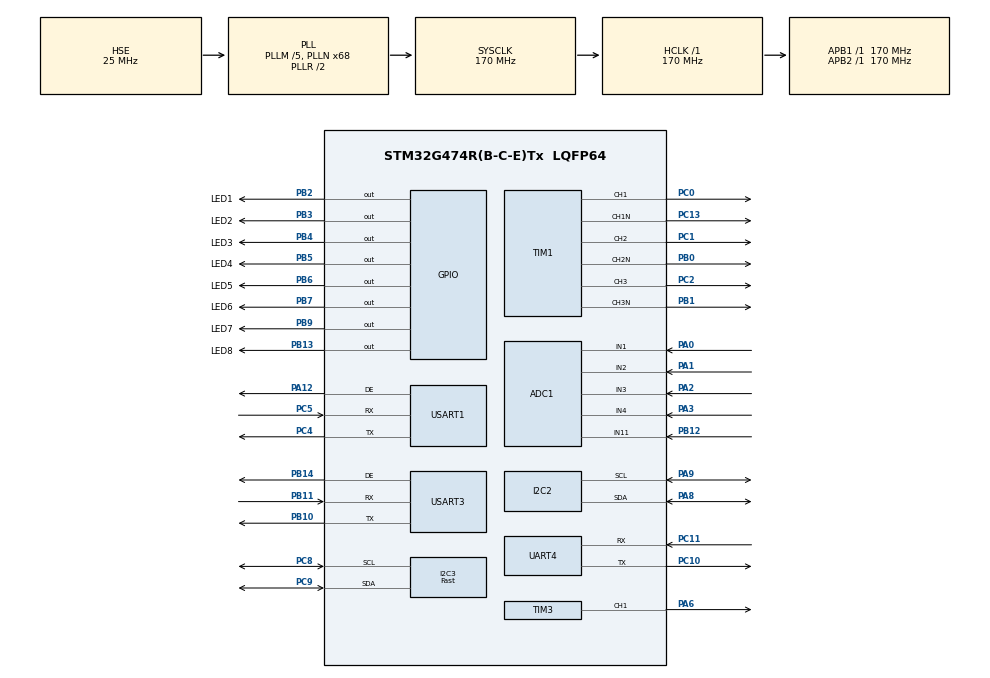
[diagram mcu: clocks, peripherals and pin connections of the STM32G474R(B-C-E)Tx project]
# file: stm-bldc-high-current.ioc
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ADC1.Channel-0\#ChannelRegularConversion=ADC_CHANNEL_1
ADC1.Channel-1\#ChannelRegularConversion=ADC_CHANNEL_2
ADC1.Channel-2\#ChannelRegularConversion=ADC_CHANNEL_3
ADC1.Channel-3\#ChannelRegularConversion=ADC_CHANNEL_4
ADC1.ContinuousConvMode=DISABLE
ADC1.DMAContinuousRequests=ENABLE
ADC1.EOCSelection=ADC_EOC_SEQ_CONV
ADC1.ExternalTrigConv=ADC_EXTERNALTRIG_T1_TRGO2
ADC1.ExternalTrigConvEdge=ADC_EXTERNALTRIGCONVEDGE_RISING
ADC1.NbrOfConversion=4
ADC1.NbrOfConversionFlag=1
ADC1.OffsetNumber-0\#ChannelRegularConversion=ADC_OFFSET_NONE
ADC1.OffsetNumber-1\#ChannelRegularConversion=ADC_OFFSET_NONE
ADC1.OffsetNumber-2\#ChannelRegularConversion=ADC_OFFSET_NONE
ADC1.OffsetNumber-3\#ChannelRegularConversion=ADC_OFFSET_NONE
ADC1.Overrun=ADC_OVR_DATA_OVERWRITTEN
ADC1.Rank-0\#ChannelRegularConversion=1
ADC1.Rank-1\#ChannelRegularConversion=2
ADC1.Rank-2\#ChannelRegularConversion=3
ADC1.Rank-3\#ChannelRegularConversion=4
ADC1.SamplingTime-0\#ChannelRegularConversion=ADC_SAMPLETIME_2CYCLES_5
ADC1.SamplingTime-1\#ChannelRegularConversion=ADC_SAMPLETIME_2CYCLES_5
ADC1.SamplingTime-2\#ChannelRegularConversion=ADC_SAMPLETIME_2CYCLES_5
ADC1.SamplingTime-3\#ChannelRegularConversion=ADC_SAMPLETIME_12CYCLES_5
ADC1.master=1
Dma.ADC1.0.Direction=DMA_PERIPH_TO_MEMORY
Dma.ADC1.0.EventEnable=DISABLE
Dma.ADC1.0.Instance=DMA1_Channel1
Dma.ADC1.0.MemDataAlignment=DMA_MDATAALIGN_HALFWORD
Dma.ADC1.0.MemInc=DMA_MINC_ENABLE
Dma.ADC1.0.Mode=DMA_CIRCULAR
Dma.ADC1.0.PeriphDataAlignment=DMA_PDATAALIGN_HALFWORD
Dma.ADC1.0.PeriphInc=DMA_PINC_DISABLE
Dma.ADC1.0.Polarity=HAL_DMAMUX_REQ_GEN_RISING
Dma.ADC1.0.Priority=DMA_PRIORITY_LOW
Dma.ADC1.0.RequestNumber=1
Dma.ADC1.0.SignalID=NONE
Dma.ADC1.0.SyncEnable=DISABLE
Dma.ADC1.0.SyncPolarity=HAL_DMAMUX_SYNC_NO_EVENT
Dma.ADC1.0.SyncRequestNumber=1
Dma.ADC1.0.SyncSignalID=NONE
Dma.Request0=ADC1
I2C2.Timing=0x40B285C2
I2C3.I2C_Speed_Mode=I2C_Fast
I2C3.Timing=0x40621236
Mcu.Family=STM32G4
Mcu.Name=STM32G474R(B-C-E)Tx
Mcu.Package=LQFP64
NVIC.I2C3_EV_IRQn=true\:0\:0\:false\:false\:true\:true\:true\:true
NVIC.PriorityGroup=NVIC_PRIORITYGROUP_4
NVIC.TIM1_UP_TIM16_IRQn=true\:0\:0\:false\:false\:true\:true\:true\:true
PA0.Mode=IN1-Single-Ended
PA0.Signal=ADC1_IN1
PA1.Mode=IN2-Single-Ended
PA1.Signal=ADC1_IN2
PA12.Mode=Hardware Flow Control (RS485)
PA12.Signal=USART1_DE
PA13.Mode=Serial_Wire
PA13.Signal=SYS_JTMS-SWDIO
PA14.Mode=Serial_Wire
PA14.Signal=SYS_JTCK-SWCLK
PA2.Mode=IN3-Single-Ended
PA2.Signal=ADC1_IN3
PA3.Mode=IN4-Single-Ended
PA3.Signal=ADC1_IN4
PA6.Signal=S_TIM3_CH1
PA8.Mode=I2C
PA8.Signal=I2C2_SDA
PA9.Mode=I2C
PA9.Signal=I2C2_SCL
PB0.Mode=PWM Generation2 CH2 CH2N
PB0.Signal=TIM1_CH2N
PB1.Mode=PWM Generation3 CH3 CH3N
PB1.Signal=TIM1_CH3N
PB10.Mode=Asynchronous
PB10.Signal=USART3_TX
PB11.Mode=Asynchronous
PB11.Signal=USART3_RX
PB12.Mode=IN11-Single-Ended
PB12.Signal=ADC1_IN11
PB13.GPIO_Label=LED8
PB13.Signal=GPIO_Output
PB14.Mode=Hardware Flow Control (RS485)
PB14.Signal=USART3_DE
PB2.GPIO_Label=LED1
PB2.Signal=GPIO_Output
PB3.GPIO_Label=LED2
PB3.Signal=GPIO_Output
PB4.GPIO_Label=LED3
PB4.Signal=GPIO_Output
PB5.GPIO_Label=LED4
PB5.Signal=GPIO_Output
PB6.GPIO_Label=LED5
PB6.Signal=GPIO_Output
PB7.GPIO_Label=LED6
PB7.Signal=GPIO_Output
PB9.GPIO_Label=LED7
PB9.Signal=GPIO_Output
PC0.Signal=S_TIM1_CH1
PC1.Signal=S_TIM1_CH2
PC10.Mode=Asynchronous
PC10.Signal=UART4_TX
PC11.Mode=Asynchronous
PC11.Signal=UART4_RX
PC13.Mode=PWM Generation1 CH1 CH1N
PC13.Signal=TIM1_CH1N
PC2.Signal=S_TIM1_CH3
PC4.Mode=Asynchronous
PC4.Signal=USART1_TX
PC5.Mode=Asynchronous
PC5.Signal=USART1_RX
PC8.Mode=I2C
PC8.Signal=I2C3_SCL
PC9.Mode=I2C
PC9.Signal=I2C3_SDA
PF0-OSC_IN.Mode=HSE-External-Oscillator
PF0-OSC_IN.Signal=RCC_OSC_IN
PF1-OSC_OUT.Mode=HSE-External-Oscillator
PF1-OSC_OUT.Signal=RCC_OSC_OUT
ProjectManager.HeapSize=0x200
ProjectManager.StackSize=0x400
ProjectManager.TargetToolchain=STM32CubeIDE
RCC.ADC12Freq_Value=170000000
RCC.ADC345Freq_Value=170000000
RCC.AHBFreq_Value=170000000
RCC.APB1Freq_Value=170000000
RCC.APB1TimFreq_Value=170000000
RCC.APB2Freq_Value=170000000
RCC.APB2TimFreq_Value=170000000
RCC.CortexFreq_Value=170000000
RCC.EXTERNAL_CLOCK_VALUE=12288000
RCC.HCLKFreq_Value=170000000
RCC.HSE_VALUE=25000000
RCC.HSI48_VALUE=48000000
RCC.HSI_VALUE=16000000
RCC.LSE_VALUE=32768
RCC.PLLM=RCC_PLLM_DIV5
RCC.PLLN=68
RCC.PLLSourceVirtual=RCC_PLLSOURCE_HSE
RCC.SYSCLKFreq_VALUE=170000000
RCC.SYSCLKSource=RCC_SYSCLKSOURCE_PLLCLK
RCC.USBFreq_Value=170000000
RCC.VCOOutputFreq_Value=340000000
SH.S_TIM1_CH1.0=TIM1_CH1,PWM Generation1 CH1 CH1N
SH.S_TIM1_CH2.0=TIM1_CH2,PWM Generation2 CH2 CH2N
SH.S_TIM1_CH3.0=TIM1_CH3,PWM Generation3 CH3 CH3N
SH.S_TIM3_CH1.0=TIM3_CH1,PWM Generation1 CH1
TIM1.AutoReloadPreload=TIM_AUTORELOAD_PRELOAD_ENABLE
TIM1.Channel-PWM\ Generation1\ CH1\ CH1N=TIM_CHANNEL_1
TIM1.Channel-PWM\ Generation2\ CH2\ CH2N=TIM_CHANNEL_2
TIM1.Channel-PWM\ Generation3\ CH3\ CH3N=TIM_CHANNEL_3
TIM1.Channel-PWM\ Generation6\ No\ Output=TIM_CHANNEL_6
TIM1.CounterMode=TIM_COUNTERMODE_CENTERALIGNED1
TIM1.DeadTime=65
TIM1.OCMode_PWM-PWM\ Generation1\ CH1\ CH1N=TIM_OCMODE_PWM1
TIM1.PulseNoDither_6=5
TIM1.TIM_MasterOutputTrigger=TIM_TRGO_UPDATE
TIM1.TIM_MasterOutputTrigger2=TIM_TRGO2_OC6REF
TIM1.TIM_MasterSlaveMode=TIM_MASTERSLAVEMODE_ENABLE
TIM3.Channel-Output\ Compare4\ No\ Output=TIM_CHANNEL_4
TIM3.Channel-PWM\ Generation1\ CH1=TIM_CHANNEL_1
TIM3.OCMode_4=TIM_OCMODE_ACTIVE
TIM3.PeriodNoDither=65535
TIM3.PulseNoDither_4=1
TIM3.TIM_MasterOutputTrigger=TIM_TRGO_RESET
TIM3.TIM_MasterSlaveMode=TIM_MASTERSLAVEMODE_DISABLE
USART1.VirtualMode-Asynchronous=VM_ASYNC
USART1.VirtualMode-Hardware\ Flow\ Control\ (RS485)=VM_ASYNC
USART3.VirtualMode-Asynchronous=VM_ASYNC
USART3.VirtualMode-Hardware\ Flow\ Control\ (RS485)=VM_ASYNC
VP_SYS_VS_DBSignals.Mode=DisableDeadBatterySignals
VP_TIM1_VS_no_output6.Mode=PWM Generation6 No Output
VP_TIM3_VS_ClockSourceINT.Mode=Internal
VP_TIM3_VS_ClockSourceITR.Mode=TriggerSource_ITR0
VP_TIM3_VS_ControllerModeReset.Mode=Reset Mode
VP_TIM3_VS_no_output4.Mode=Output Compare4 No Output
board=custom

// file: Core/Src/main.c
/* USER CODE BEGIN Header */
/**
  ******************************************************************************
  * @file           : main.c
  * @brief          : Main program body
  ******************************************************************************
  * @attention
  *
  * Copyright (c) 2025 STMicroelectronics.
  * All rights reserved.
  *
  * This software is licensed under terms that can be found in the LICENSE file
  * in the root directory of this software component.
  * If no LICENSE file comes with this software, it is provided AS-IS.
  *
  ******************************************************************************
  */
/* USER CODE END Header */
#include "main.h"

/* USER CODE BEGIN Includes */
#include "application.h"
/* USER CODE END Includes */

ADC_HandleTypeDef hadc1;
DMA_HandleTypeDef hdma_adc1;

I2C_HandleTypeDef hi2c2;
I2C_HandleTypeDef hi2c3;

TIM_HandleTypeDef htim1;
TIM_HandleTypeDef htim3;

UART_HandleTypeDef huart4;
UART_HandleTypeDef huart1;
UART_HandleTypeDef huart3;

void SystemClock_Config(void);
static void MX_GPIO_Init(void);
static void MX_DMA_Init(void);
static void MX_ADC1_Init(void);
static void MX_TIM1_Init(void);
static void MX_USART1_UART_Init(void);
static void MX_USART3_UART_Init(void);
static void MX_I2C2_Init(void);
static void MX_I2C3_Init(void);
static void MX_UART4_Init(void);
static void MX_TIM3_Init(void);

int main(void)
{

  /* MCU Configuration--------------------------------------------------------*/

  /* Reset of all peripherals, Initializes the Flash interface and the Systick. */
  HAL_Init();

  /* Configure the system clock */
  SystemClock_Config();

  /* Initialize all configured peripherals */
  MX_GPIO_Init();
  MX_DMA_Init();
  MX_ADC1_Init();
  MX_TIM1_Init();
  MX_USART1_UART_Init();
  MX_USART3_UART_Init();
  MX_I2C2_Init();
  MX_I2C3_Init();
  MX_UART4_Init();
  MX_TIM3_Init();

  /* Infinite loop */
  /* USER CODE BEGIN WHILE */
  application_init();
  while (1)
  {
	  application_loop();
    /* USER CODE END WHILE */

  }
}

void SystemClock_Config(void)
{
  RCC_OscInitTypeDef RCC_OscInitStruct = {0};
  RCC_ClkInitTypeDef RCC_ClkInitStruct = {0};

  /** Configure the main internal regulator output voltage
  */
  HAL_PWREx_ControlVoltageScaling(PWR_REGULATOR_VOLTAGE_SCALE1_BOOST);

  /** Initializes the RCC Oscillators according to the specified parameters
  * in the RCC_OscInitTypeDef structure.
  */
  RCC_OscInitStruct.OscillatorType = RCC_OSCILLATORTYPE_HSE;
  RCC_OscInitStruct.HSEState = RCC_HSE_ON;
  RCC_OscInitStruct.PLL.PLLState = RCC_PLL_ON;
  RCC_OscInitStruct.PLL.PLLSource = RCC_PLLSOURCE_HSE;
  RCC_OscInitStruct.PLL.PLLM = RCC_PLLM_DIV5;
  RCC_OscInitStruct.PLL.PLLN = 68;
  RCC_OscInitStruct.PLL.PLLP = RCC_PLLP_DIV2;
  RCC_OscInitStruct.PLL.PLLQ = RCC_PLLQ_DIV2;
  RCC_OscInitStruct.PLL.PLLR = RCC_PLLR_DIV2;
  if (HAL_RCC_OscConfig(&RCC_OscInitStruct) != HAL_OK)
  {
    Error_Handler();
  }

  /** Initializes the CPU, AHB and APB buses clocks
  */
  RCC_ClkInitStruct.ClockType = RCC_CLOCKTYPE_HCLK|RCC_CLOCKTYPE_SYSCLK
                              |RCC_CLOCKTYPE_PCLK1|RCC_CLOCKTYPE_PCLK2;
  RCC_ClkInitStruct.SYSCLKSource = RCC_SYSCLKSOURCE_PLLCLK;
  RCC_ClkInitStruct.AHBCLKDivider = RCC_SYSCLK_DIV1;
  RCC_ClkInitStruct.APB1CLKDivider = RCC_HCLK_DIV1;
  RCC_ClkInitStruct.APB2CLKDivider = RCC_HCLK_DIV1;

  if (HAL_RCC_ClockConfig(&RCC_ClkInitStruct, FLASH_LATENCY_4) != HAL_OK)
  {
    Error_Handler();
  }
}

static void MX_ADC1_Init(void)
{

  ADC_MultiModeTypeDef multimode = {0};
  ADC_ChannelConfTypeDef sConfig = {0};

  /** Common config
  */
  hadc1.Instance = ADC1;
  hadc1.Init.ClockPrescaler = ADC_CLOCK_SYNC_PCLK_DIV4;
  hadc1.Init.Resolution = ADC_RESOLUTION_12B;
  hadc1.Init.DataAlign = ADC_DATAALIGN_RIGHT;
  hadc1.Init.GainCompensation = 0;
  hadc1.Init.ScanConvMode = ADC_SCAN_ENABLE;
  hadc1.Init.EOCSelection = ADC_EOC_SEQ_CONV;
  hadc1.Init.LowPowerAutoWait = DISABLE;
  hadc1.Init.ContinuousConvMode = DISABLE;
  hadc1.Init.NbrOfConversion = 4;
  hadc1.Init.DiscontinuousConvMode = DISABLE;
  hadc1.Init.ExternalTrigConv = ADC_EXTERNALTRIG_T1_TRGO2;
  hadc1.Init.ExternalTrigConvEdge = ADC_EXTERNALTRIGCONVEDGE_RISING;
  hadc1.Init.DMAContinuousRequests = ENABLE;
  hadc1.Init.Overrun = ADC_OVR_DATA_OVERWRITTEN;
  hadc1.Init.OversamplingMode = DISABLE;
  if (HAL_ADC_Init(&hadc1) != HAL_OK)
  {
    Error_Handler();
  }

  /** Configure the ADC multi-mode
  */
  multimode.Mode = ADC_MODE_INDEPENDENT;
  if (HAL_ADCEx_MultiModeConfigChannel(&hadc1, &multimode) != HAL_OK)
  {
    Error_Handler();
  }

  /** Configure Regular Channel
  */
  sConfig.Channel = ADC_CHANNEL_1;
  sConfig.Rank = ADC_REGULAR_RANK_1;
  sConfig.SamplingTime = ADC_SAMPLETIME_2CYCLES_5;
  sConfig.SingleDiff = ADC_SINGLE_ENDED;
  sConfig.OffsetNumber = ADC_OFFSET_NONE;
  sConfig.Offset = 0;
  if (HAL_ADC_ConfigChannel(&hadc1, &sConfig) != HAL_OK)
  {
    Error_Handler();
  }

  /** Configure Regular Channel
  */
  sConfig.Channel = ADC_CHANNEL_2;
  sConfig.Rank = ADC_REGULAR_RANK_2;
  if (HAL_ADC_ConfigChannel(&hadc1, &sConfig) != HAL_OK)
  {
    Error_Handler();
  }

  /** Configure Regular Channel
  */
  sConfig.Channel = ADC_CHANNEL_3;
  sConfig.Rank = ADC_REGULAR_RANK_3;
  if (HAL_ADC_ConfigChannel(&hadc1, &sConfig) != HAL_OK)
  {
    Error_Handler();
  }

  /** Configure Regular Channel
  */
  sConfig.Channel = ADC_CHANNEL_4;
  sConfig.Rank = ADC_REGULAR_RANK_4;
  sConfig.SamplingTime = ADC_SAMPLETIME_12CYCLES_5;
  if (HAL_ADC_ConfigChannel(&hadc1, &sConfig) != HAL_OK)
  {
    Error_Handler();
  }

}

static void MX_I2C2_Init(void)
{

  hi2c2.Instance = I2C2;
  hi2c2.Init.Timing = 0x40B285C2;
  hi2c2.Init.OwnAddress1 = 0;
  hi2c2.Init.AddressingMode = I2C_ADDRESSINGMODE_7BIT;
  hi2c2.Init.DualAddressMode = I2C_DUALADDRESS_DISABLE;
  hi2c2.Init.OwnAddress2 = 0;
  hi2c2.Init.OwnAddress2Masks = I2C_OA2_NOMASK;
  hi2c2.Init.GeneralCallMode = I2C_GENERALCALL_DISABLE;
  hi2c2.Init.NoStretchMode = I2C_NOSTRETCH_DISABLE;
  if (HAL_I2C_Init(&hi2c2) != HAL_OK)
  {
    Error_Handler();
  }

  /** Configure Analogue filter
  */
  if (HAL_I2CEx_ConfigAnalogFilter(&hi2c2, I2C_ANALOGFILTER_ENABLE) != HAL_OK)
  {
    Error_Handler();
  }

  /** Configure Digital filter
  */
  if (HAL_I2CEx_ConfigDigitalFilter(&hi2c2, 0) != HAL_OK)
  {
    Error_Handler();
  }

}

static void MX_I2C3_Init(void)
{

  hi2c3.Instance = I2C3;
  hi2c3.Init.Timing = 0x40621236;
  hi2c3.Init.OwnAddress1 = 0;
  hi2c3.Init.AddressingMode = I2C_ADDRESSINGMODE_7BIT;
  hi2c3.Init.DualAddressMode = I2C_DUALADDRESS_DISABLE;
  hi2c3.Init.OwnAddress2 = 0;
  hi2c3.Init.OwnAddress2Masks = I2C_OA2_NOMASK;
  hi2c3.Init.GeneralCallMode = I2C_GENERALCALL_DISABLE;
  hi2c3.Init.NoStretchMode = I2C_NOSTRETCH_DISABLE;
  if (HAL_I2C_Init(&hi2c3) != HAL_OK)
  {
    Error_Handler();
  }

  /** Configure Analogue filter
  */
  if (HAL_I2CEx_ConfigAnalogFilter(&hi2c3, I2C_ANALOGFILTER_ENABLE) != HAL_OK)
  {
    Error_Handler();
  }

  /** Configure Digital filter
  */
  if (HAL_I2CEx_ConfigDigitalFilter(&hi2c3, 0) != HAL_OK)
  {
    Error_Handler();
  }

}

static void MX_TIM1_Init(void)
{

  TIM_MasterConfigTypeDef sMasterConfig = {0};
  TIM_OC_InitTypeDef sConfigOC = {0};
  TIM_BreakDeadTimeConfigTypeDef sBreakDeadTimeConfig = {0};

  htim1.Instance = TIM1;
  htim1.Init.Prescaler = 0;
  htim1.Init.CounterMode = TIM_COUNTERMODE_CENTERALIGNED1;
  htim1.Init.Period = 65535;
  htim1.Init.ClockDivision = TIM_CLOCKDIVISION_DIV1;
  htim1.Init.RepetitionCounter = 0;
  htim1.Init.AutoReloadPreload = TIM_AUTORELOAD_PRELOAD_ENABLE;
  if (HAL_TIM_PWM_Init(&htim1) != HAL_OK)
  {
    Error_Handler();
  }
  sMasterConfig.MasterOutputTrigger = TIM_TRGO_UPDATE;
  sMasterConfig.MasterOutputTrigger2 = TIM_TRGO2_OC6REF;
  sMasterConfig.MasterSlaveMode = TIM_MASTERSLAVEMODE_ENABLE;
  if (HAL_TIMEx_MasterConfigSynchronization(&htim1, &sMasterConfig) != HAL_OK)
  {
    Error_Handler();
  }
  sConfigOC.OCMode = TIM_OCMODE_PWM1;
  sConfigOC.Pulse = 0;
  sConfigOC.OCPolarity = TIM_OCPOLARITY_HIGH;
  sConfigOC.OCNPolarity = TIM_OCNPOLARITY_HIGH;
  sConfigOC.OCFastMode = TIM_OCFAST_DISABLE;
  sConfigOC.OCIdleState = TIM_OCIDLESTATE_RESET;
  sConfigOC.OCNIdleState = TIM_OCNIDLESTATE_RESET;
  if (HAL_TIM_PWM_ConfigChannel(&htim1, &sConfigOC, TIM_CHANNEL_1) != HAL_OK)
  {
    Error_Handler();
  }
  if (HAL_TIM_PWM_ConfigChannel(&htim1, &sConfigOC, TIM_CHANNEL_2) != HAL_OK)
  {
    Error_Handler();
  }
  if (HAL_TIM_PWM_ConfigChannel(&htim1, &sConfigOC, TIM_CHANNEL_3) != HAL_OK)
  {
    Error_Handler();
  }
  sConfigOC.Pulse = 5;
  if (HAL_TIM_PWM_ConfigChannel(&htim1, &sConfigOC, TIM_CHANNEL_6) != HAL_OK)
  {
    Error_Handler();
  }
  sBreakDeadTimeConfig.OffStateRunMode = TIM_OSSR_DISABLE;
  sBreakDeadTimeConfig.OffStateIDLEMode = TIM_OSSI_DISABLE;
  sBreakDeadTimeConfig.LockLevel = TIM_LOCKLEVEL_OFF;
  sBreakDeadTimeConfig.DeadTime = 65;
  sBreakDeadTimeConfig.BreakState = TIM_BREAK_DISABLE;
  sBreakDeadTimeConfig.BreakPolarity = TIM_BREAKPOLARITY_HIGH;
  sBreakDeadTimeConfig.BreakFilter = 0;
  sBreakDeadTimeConfig.BreakAFMode = TIM_BREAK_AFMODE_INPUT;
  sBreakDeadTimeConfig.Break2State = TIM_BREAK2_DISABLE;
  sBreakDeadTimeConfig.Break2Polarity = TIM_BREAK2POLARITY_HIGH;
  sBreakDeadTimeConfig.Break2Filter = 0;
  sBreakDeadTimeConfig.Break2AFMode = TIM_BREAK_AFMODE_INPUT;
  sBreakDeadTimeConfig.AutomaticOutput = TIM_AUTOMATICOUTPUT_DISABLE;
  if (HAL_TIMEx_ConfigBreakDeadTime(&htim1, &sBreakDeadTimeConfig) != HAL_OK)
  {
    Error_Handler();
  }
  HAL_TIM_MspPostInit(&htim1);

}

static void MX_TIM3_Init(void)
{

  TIM_ClockConfigTypeDef sClockSourceConfig = {0};
  TIM_SlaveConfigTypeDef sSlaveConfig = {0};
  TIM_MasterConfigTypeDef sMasterConfig = {0};
  TIM_OC_InitTypeDef sConfigOC = {0};

  htim3.Instance = TIM3;
  htim3.Init.Prescaler = 0;
  htim3.Init.CounterMode = TIM_COUNTERMODE_UP;
  htim3.Init.Period = 65535;
  htim3.Init.ClockDivision = TIM_CLOCKDIVISION_DIV1;
  htim3.Init.AutoReloadPreload = TIM_AUTORELOAD_PRELOAD_DISABLE;
  if (HAL_TIM_Base_Init(&htim3) != HAL_OK)
  {
    Error_Handler();
  }
  sClockSourceConfig.ClockSource = TIM_CLOCKSOURCE_INTERNAL;
  if (HAL_TIM_ConfigClockSource(&htim3, &sClockSourceConfig) != HAL_OK)
  {
    Error_Handler();
  }
  if (HAL_TIM_PWM_Init(&htim3) != HAL_OK)
  {
    Error_Handler();
  }
  if (HAL_TIM_OC_Init(&htim3) != HAL_OK)
  {
    Error_Handler();
  }
  sSlaveConfig.SlaveMode = TIM_SLAVEMODE_RESET;
  sSlaveConfig.InputTrigger = TIM_TS_ITR0;
  if (HAL_TIM_SlaveConfigSynchro(&htim3, &sSlaveConfig) != HAL_OK)
  {
    Error_Handler();
  }
  sMasterConfig.MasterOutputTrigger = TIM_TRGO_RESET;
  sMasterConfig.MasterSlaveMode = TIM_MASTERSLAVEMODE_DISABLE;
  if (HAL_TIMEx_MasterConfigSynchronization(&htim3, &sMasterConfig) != HAL_OK)
  {
    Error_Handler();
  }
  sConfigOC.OCMode = TIM_OCMODE_PWM1;
  sConfigOC.Pulse = 0;
  sConfigOC.OCPolarity = TIM_OCPOLARITY_HIGH;
  sConfigOC.OCFastMode = TIM_OCFAST_DISABLE;
  if (HAL_TIM_PWM_ConfigChannel(&htim3, &sConfigOC, TIM_CHANNEL_1) != HAL_OK)
  {
    Error_Handler();
  }
  sConfigOC.OCMode = TIM_OCMODE_ACTIVE;
  sConfigOC.Pulse = 1;
  if (HAL_TIM_OC_ConfigChannel(&htim3, &sConfigOC, TIM_CHANNEL_4) != HAL_OK)
  {
    Error_Handler();
  }
  HAL_TIM_MspPostInit(&htim3);

}

static void MX_UART4_Init(void)
{

  huart4.Instance = UART4;
  huart4.Init.BaudRate = 115200;
  huart4.Init.WordLength = UART_WORDLENGTH_8B;
  huart4.Init.StopBits = UART_STOPBITS_1;
  huart4.Init.Parity = UART_PARITY_NONE;
  huart4.Init.Mode = UART_MODE_TX_RX;
  huart4.Init.HwFlowCtl = UART_HWCONTROL_NONE;
  huart4.Init.OverSampling = UART_OVERSAMPLING_16;
  huart4.Init.OneBitSampling = UART_ONE_BIT_SAMPLE_DISABLE;
  huart4.Init.ClockPrescaler = UART_PRESCALER_DIV1;
  huart4.AdvancedInit.AdvFeatureInit = UART_ADVFEATURE_NO_INIT;
  if (HAL_UART_Init(&huart4) != HAL_OK)
  {
    Error_Handler();
  }
  if (HAL_UARTEx_SetTxFifoThreshold(&huart4, UART_TXFIFO_THRESHOLD_1_8) != HAL_OK)
  {
    Error_Handler();
  }
  if (HAL_UARTEx_SetRxFifoThreshold(&huart4, UART_RXFIFO_THRESHOLD_1_8) != HAL_OK)
  {
    Error_Handler();
  }
  if (HAL_UARTEx_DisableFifoMode(&huart4) != HAL_OK)
  {
    Error_Handler();
  }

}

static void MX_USART1_UART_Init(void)
{

  huart1.Instance = USART1;
  huart1.Init.BaudRate = 115200;
  huart1.Init.WordLength = UART_WORDLENGTH_8B;
  huart1.Init.StopBits = UART_STOPBITS_1;
  huart1.Init.Parity = UART_PARITY_NONE;
  huart1.Init.Mode = UART_MODE_TX_RX;
  huart1.Init.HwFlowCtl = UART_HWCONTROL_NONE;
  huart1.Init.OverSampling = UART_OVERSAMPLING_16;
  huart1.Init.OneBitSampling = UART_ONE_BIT_SAMPLE_DISABLE;
  huart1.Init.ClockPrescaler = UART_PRESCALER_DIV1;
  huart1.AdvancedInit.AdvFeatureInit = UART_ADVFEATURE_NO_INIT;
  if (HAL_RS485Ex_Init(&huart1, UART_DE_POLARITY_HIGH, 0, 0) != HAL_OK)
  {
    Error_Handler();
  }
  if (HAL_UARTEx_SetTxFifoThreshold(&huart1, UART_TXFIFO_THRESHOLD_1_8) != HAL_OK)
  {
    Error_Handler();
  }
  if (HAL_UARTEx_SetRxFifoThreshold(&huart1, UART_RXFIFO_THRESHOLD_1_8) != HAL_OK)
  {
    Error_Handler();
  }
  if (HAL_UARTEx_DisableFifoMode(&huart1) != HAL_OK)
  {
    Error_Handler();
  }

}

static void MX_USART3_UART_Init(void)
{

  huart3.Instance = USART3;
  huart3.Init.BaudRate = 115200;
  huart3.Init.WordLength = UART_WORDLENGTH_8B;
  huart3.Init.StopBits = UART_STOPBITS_1;
  huart3.Init.Parity = UART_PARITY_NONE;
  huart3.Init.Mode = UART_MODE_TX_RX;
  huart3.Init.HwFlowCtl = UART_HWCONTROL_NONE;
  huart3.Init.OverSampling = UART_OVERSAMPLING_16;
  huart3.Init.OneBitSampling = UART_ONE_BIT_SAMPLE_DISABLE;
  huart3.Init.ClockPrescaler = UART_PRESCALER_DIV1;
  huart3.AdvancedInit.AdvFeatureInit = UART_ADVFEATURE_NO_INIT;
  if (HAL_RS485Ex_Init(&huart3, UART_DE_POLARITY_HIGH, 0, 0) != HAL_OK)
  {
    Error_Handler();
  }
  if (HAL_UARTEx_SetTxFifoThreshold(&huart3, UART_TXFIFO_THRESHOLD_1_8) != HAL_OK)
  {
    Error_Handler();
  }
  if (HAL_UARTEx_SetRxFifoThreshold(&huart3, UART_RXFIFO_THRESHOLD_1_8) != HAL_OK)
  {
    Error_Handler();
  }
  if (HAL_UARTEx_DisableFifoMode(&huart3) != HAL_OK)
  {
    Error_Handler();
  }

}

static void MX_DMA_Init(void)
{

  /* DMA controller clock enable */
  __HAL_RCC_DMAMUX1_CLK_ENABLE();
  __HAL_RCC_DMA1_CLK_ENABLE();

}

static void MX_GPIO_Init(void)
{
  GPIO_InitTypeDef GPIO_InitStruct = {0};

  /* GPIO Ports Clock Enable */
  __HAL_RCC_GPIOC_CLK_ENABLE();
  __HAL_RCC_GPIOF_CLK_ENABLE();
  __HAL_RCC_GPIOA_CLK_ENABLE();
  __HAL_RCC_GPIOB_CLK_ENABLE();

  /*Configure GPIO pin Output Level */
  HAL_GPIO_WritePin(GPIOB, LED1_Pin|LED8_Pin|LED2_Pin|LED3_Pin
                          |LED4_Pin|LED5_Pin|LED6_Pin|LED7_Pin, GPIO_PIN_RESET);

  /*Configure GPIO pins : LED1_Pin LED8_Pin LED2_Pin LED3_Pin
                           LED4_Pin LED5_Pin LED6_Pin LED7_Pin */
  GPIO_InitStruct.Pin = LED1_Pin|LED8_Pin|LED2_Pin|LED3_Pin
                          |LED4_Pin|LED5_Pin|LED6_Pin|LED7_Pin;
  GPIO_InitStruct.Mode = GPIO_MODE_OUTPUT_PP;
  GPIO_InitStruct.Pull = GPIO_NOPULL;
  GPIO_InitStruct.Speed = GPIO_SPEED_FREQ_LOW;
  HAL_GPIO_Init(GPIOB, &GPIO_InitStruct);

}

void Error_Handler(void)
{
  __disable_irq();
  while (1)
  {
  }
}
